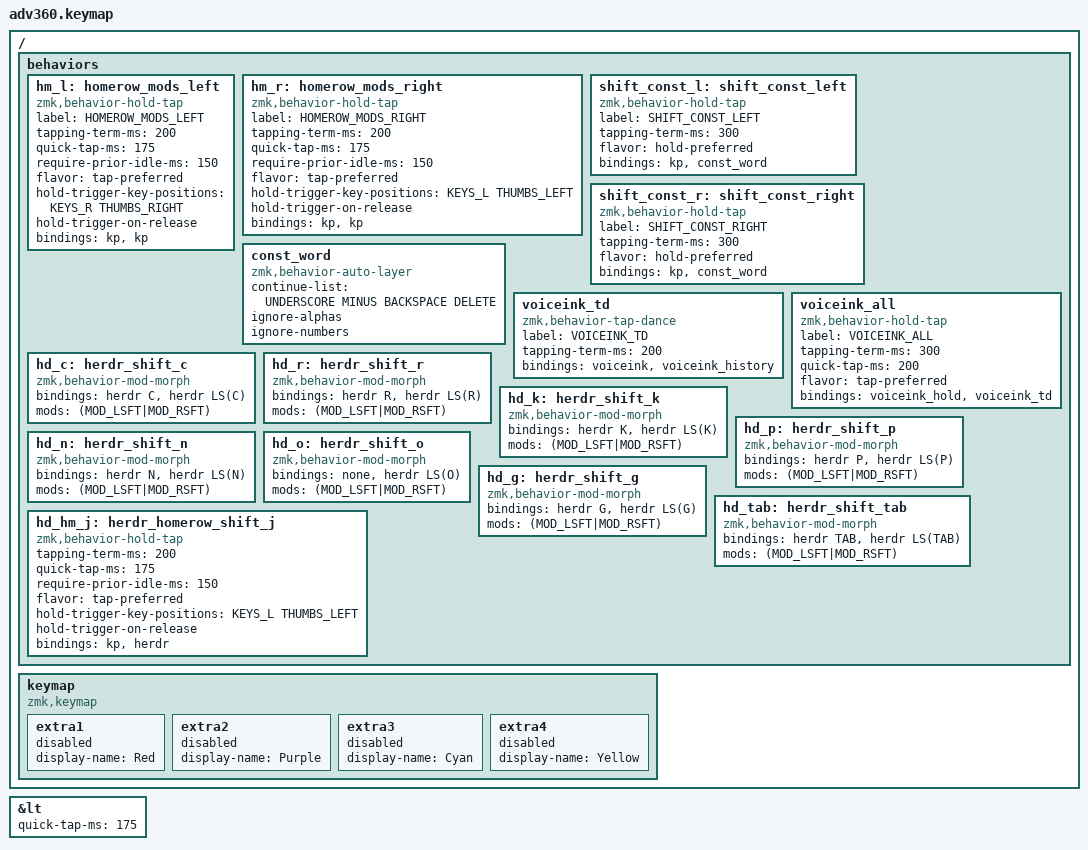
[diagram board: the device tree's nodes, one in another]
#include <behaviors.dtsi>
#include <dt-bindings/zmk/keys.h>
#include <dt-bindings/zmk/bt.h>
#include <dt-bindings/zmk/rgb.h>
#include <dt-bindings/zmk/stp.h>
#include <dt-bindings/zmk/backlight.h>
#include <dt-bindings/zmk/pointing.h>
#include <behaviors/num_word.dtsi>

// Key position definitions for homerow mods
#define KEYS_L 0 1 2 3 4 5 6 14 15 16 17 18 19 20 28 29 30 31 32 33 34 46 47 48 49 50 51 60 61 62 63 64   // Left side keys  
#define KEYS_R 7 8 9 10 11 12 13 21 22 23 24 25 26 27 39 40 41 42 43 44 45 54 55 56 57 58 59 71 72 73 74 75 // Right side keys

#define THUMBS_LEFT  35 36 52 65 66 67   // Left thumb cluster
#define THUMBS_RIGHT 37 38 53 68 69 70   // Right thumb cluster

// Layer-tap tuning (used by &lt 1 LC(B) on position 65): tap, then press again
// within 175ms re-taps the key instead of holding the layer.
&lt {
    quick-tap-ms = <175>;
};

/ {
    behaviors {
      #include "macros.dtsi"
      #include "version.dtsi"

      // Left-hand homerow mods (only activate with right-hand keys)
      hm_l: homerow_mods_left {
          compatible = "zmk,behavior-hold-tap";
          label = "HOMEROW_MODS_LEFT";
          #binding-cells = <2>;
          tapping-term-ms = <200>;
          quick-tap-ms = <175>;
          require-prior-idle-ms = <150>;
          flavor = "tap-preferred";
          hold-trigger-key-positions = <KEYS_R THUMBS_RIGHT>; // Doesn't do anything
          hold-trigger-on-release;
          bindings = <&kp>, <&kp>;
      };

      // Right-hand homerow mods (only activate with left-hand keys)  
      hm_r: homerow_mods_right {
          compatible = "zmk,behavior-hold-tap";
          label = "HOMEROW_MODS_RIGHT";
          #binding-cells = <2>;
          tapping-term-ms = <200>;
          quick-tap-ms = <175>;
          require-prior-idle-ms = <150>;
          flavor = "tap-preferred";
          hold-trigger-key-positions = <KEYS_L THUMBS_LEFT>; // Doesn't do anything
          hold-trigger-on-release;
          bindings = <&kp>, <&kp>;
      };

      // Shift with caps word on tap
      shift_const_l: shift_const_left {
          compatible = "zmk,behavior-hold-tap";
          label = "SHIFT_CONST_LEFT";
          #binding-cells = <2>;
          tapping-term-ms = <300>;
          flavor = "hold-preferred";
          bindings = <&kp>, <&const_word>;
      };

      shift_const_r: shift_const_right {
          compatible = "zmk,behavior-hold-tap";
          label = "SHIFT_CONST_RIGHT";
          #binding-cells = <2>;
          tapping-term-ms = <300>;
          flavor = "hold-preferred";
          bindings = <&kp>, <&const_word>;
      };

      // Custom auto-layer for constants with symbols
      const_word: const_word {
          compatible = "zmk,behavior-auto-layer";
          #binding-cells = <1>;
          continue-list = <UNDERSCORE MINUS BACKSPACE DELETE>;
          ignore-alphas;
          ignore-numbers;
      };

      // Tap-dance for VoiceInk (single tap) and VoiceInk History (double tap)
      voiceink_td: voiceink_td {
          compatible = "zmk,behavior-tap-dance";
          label = "VOICEINK_TD";
          #binding-cells = <0>;
          tapping-term-ms = <200>;
          bindings = <&voiceink>, <&voiceink_history>;
      };

      // Hold-tap: hold for push-to-talk, tap for tap-dance
      voiceink_all: voiceink_all {
          compatible = "zmk,behavior-hold-tap";
          label = "VOICEINK_ALL";
          #binding-cells = <2>;
          tapping-term-ms = <300>;
          quick-tap-ms = <200>;
          flavor = "tap-preferred";
          bindings = <&voiceink_hold>, <&voiceink_td>;
      };

      // herdr layer, shifted workspace keys. herdr only accepts a plain Ctrl+B
      // prefix, so with Shift held these mask the physical Shift (set on press,
      // cleared on release) and send Ctrl+B then Shift+<key> from the macro.

      hd_c: herdr_shift_c {
          compatible = "zmk,behavior-mod-morph";
          #binding-cells = <0>;
          bindings = <&herdr C>, <&herdr LS(C)>;
          mods = <(MOD_LSFT|MOD_RSFT)>;
      };

      hd_r: herdr_shift_r {
          compatible = "zmk,behavior-mod-morph";
          #binding-cells = <0>;
          bindings = <&herdr R>, <&herdr LS(R)>;
          mods = <(MOD_LSFT|MOD_RSFT)>;
      };

      hd_k: herdr_shift_k {
          compatible = "zmk,behavior-mod-morph";
          #binding-cells = <0>;
          bindings = <&herdr K>, <&herdr LS(K)>;
          mods = <(MOD_LSFT|MOD_RSFT)>;
      };

      hd_p: herdr_shift_p {
          compatible = "zmk,behavior-mod-morph";
          #binding-cells = <0>;
          bindings = <&herdr P>, <&herdr LS(P)>;
          mods = <(MOD_LSFT|MOD_RSFT)>;
      };

      hd_n: herdr_shift_n {
          compatible = "zmk,behavior-mod-morph";
          #binding-cells = <0>;
          bindings = <&herdr N>, <&herdr LS(N)>;
          mods = <(MOD_LSFT|MOD_RSFT)>;
      };

      hd_o: herdr_shift_o {
          compatible = "zmk,behavior-mod-morph";
          #binding-cells = <0>;
          bindings = <&none>, <&herdr LS(O)>;
          mods = <(MOD_LSFT|MOD_RSFT)>;
      };
      hd_g: herdr_shift_g {
          compatible = "zmk,behavior-mod-morph";
          #binding-cells = <0>;
          bindings = <&herdr G>, <&herdr LS(G)>;
          mods = <(MOD_LSFT|MOD_RSFT)>;
      };
      hd_tab: herdr_shift_tab {
          compatible = "zmk,behavior-mod-morph";
          #binding-cells = <0>;
          bindings = <&herdr TAB>, <&herdr LS(TAB)>;
          mods = <(MOD_LSFT|MOD_RSFT)>;
      };

      // herdr layer, J: keep the home-row Shift on hold (same timing as hm_r) so
      // thumb + J held + C/R reaches the shifted workspace keys; tap = prefix + j.
      hd_hm_j: herdr_homerow_shift_j {
          compatible = "zmk,behavior-hold-tap";
          #binding-cells = <2>;
          tapping-term-ms = <200>;
          quick-tap-ms = <175>;
          require-prior-idle-ms = <150>;
          flavor = "tap-preferred";
          hold-trigger-key-positions = <KEYS_L THUMBS_LEFT>;
          hold-trigger-on-release;
          bindings = <&kp>, <&herdr>;
      };
    };

  keymap {
    compatible = "zmk,keymap";

    #include "layers/default.dtsi"
    #include "layers/herdr.dtsi"
    #include "layers/keypad.dtsi"
    #include "layers/function.dtsi"
    #include "layers/mod.dtsi"
    #include "layers/constant.dtsi"
    extra1 { 
      display-name = "Red";    
      status = "reserved";
    };

    extra2 { 
      display-name = "Purple";    
      status = "reserved";
    };

    extra3 { 
      display-name = "Cyan";    
      status = "reserved";
    };

    extra4 { 
      display-name = "Yellow";    
      status = "reserved";
    };
  };
};
